AUTOSAR XML (schema 4-2-2)
package /ComponentTypes
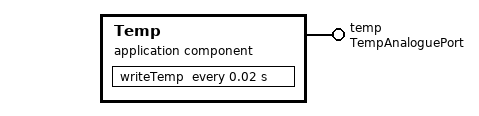
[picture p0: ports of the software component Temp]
  application sw component type Temp
    provide port temp: provided-com-specs=[{data-element=tempOut, init-value=0}, {data-element=tempIn, init-value=0}], provided-interface=TempAnaloguePort
    behavior Temp_InternalBehavior: data-type-mapping=tempMapSet
      timing event TMT_Write: start-on-event=writeTemp, period=0.02
      runnable writeTemp
        data-send-points:
          access SEND_temp_tempOut: accessed-variable=temp.tempOut
          access SEND_temp_tempIn: accessed-variable=temp.tempIn
  swc implementation Temp_Implementation: behavior=Temp_InternalBehavior
